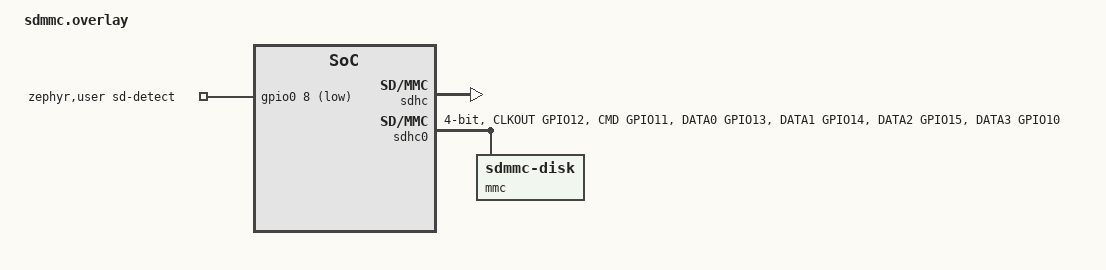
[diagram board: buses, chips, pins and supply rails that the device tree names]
/*
 * ESP32-S3 native four-bit SDMMC: GPIO12 CLK, GPIO11 CMD, GPIO13/14/15/10 DAT0-DAT3,
 * GPIO8 card detect (active low, MCU pull-up).
 */
#include <zephyr/dt-bindings/gpio/gpio.h>
#include <zephyr/dt-bindings/pinctrl/esp32s3-pinctrl.h>

/ {
	aliases {
		zephyrforge-sd = &sdhc0;
	};
	zephyr,user {
		sd-detect-gpios = <&gpio0 8 (GPIO_ACTIVE_LOW | GPIO_PULL_UP)>;
	};
};

&pinctrl {
	/* The 20 mA reset-default pad drive caused SD write CRC errors on tested hand wiring; 10 mA passed. */
	zephyrforge_sd_default: zephyrforge_sd_default {
		clock {
			pinmux = <SDHC0_CLKOUT_GPIO12>;
			drive-strength = <10>;
		};
		command_data {
			pinmux = <SDHC0_CMD_GPIO11>, <SDHC0_DATA0_GPIO13>,
				 <SDHC0_DATA1_GPIO14>, <SDHC0_DATA2_GPIO15>, <SDHC0_DATA3_GPIO10>;
			bias-pull-up;
			drive-strength = <10>;
		};
	};
};

&sdhc {
	status = "okay";
};

zephyrforge_sd: &sdhc0 {
	status = "okay";
	pinctrl-0 = <&zephyrforge_sd_default>;
	pinctrl-names = "default";
	bus-width = <4>;
	max-bus-freq = <40000000>;
	mmc {
		compatible = "zephyr,sdmmc-disk";
		disk-name = "SD";
		status = "okay";
	};
};

